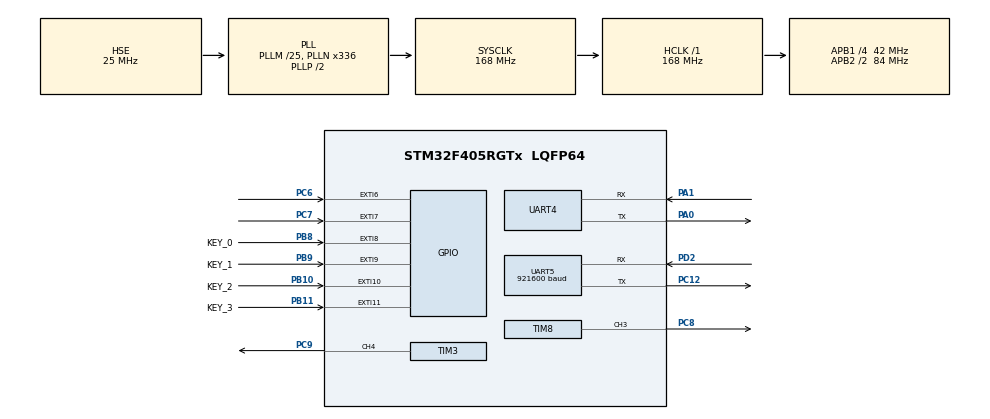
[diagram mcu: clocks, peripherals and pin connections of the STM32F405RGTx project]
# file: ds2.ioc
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Dma.Request0=UART4_RX
Dma.UART4_RX.0.Direction=DMA_PERIPH_TO_MEMORY
Dma.UART4_RX.0.FIFOMode=DMA_FIFOMODE_DISABLE
Dma.UART4_RX.0.Instance=DMA1_Stream2
Dma.UART4_RX.0.MemDataAlignment=DMA_MDATAALIGN_BYTE
Dma.UART4_RX.0.MemInc=DMA_MINC_ENABLE
Dma.UART4_RX.0.Mode=DMA_CIRCULAR
Dma.UART4_RX.0.PeriphDataAlignment=DMA_PDATAALIGN_BYTE
Dma.UART4_RX.0.PeriphInc=DMA_PINC_DISABLE
Dma.UART4_RX.0.Priority=DMA_PRIORITY_MEDIUM
Mcu.Family=STM32F4
Mcu.Name=STM32F405RGTx
Mcu.Package=LQFP64
NVIC.DMA1_Stream2_IRQn=true\:0\:0\:false\:false\:true\:false\:true\:true
NVIC.EXTI15_10_IRQn=true\:3\:0\:true\:false\:true\:true\:true\:true
NVIC.EXTI9_5_IRQn=true\:2\:0\:true\:false\:true\:true\:true\:true
NVIC.PriorityGroup=NVIC_PRIORITYGROUP_4
NVIC.TIM4_IRQn=true\:1\:0\:true\:false\:true\:true\:true\:true
NVIC.UART4_IRQn=true\:0\:0\:true\:false\:true\:true\:true\:true
PA0-WKUP.Mode=Asynchronous
PA0-WKUP.Signal=UART4_TX
PA1.Mode=Asynchronous
PA1.Signal=UART4_RX
PA13.Mode=Serial_Wire
PA13.Signal=SYS_JTMS-SWDIO
PA14.Mode=Serial_Wire
PA14.Signal=SYS_JTCK-SWCLK
PB10.GPIO_Label=KEY_2
PB10.GPIO_ModeDefaultEXTI=GPIO_MODE_IT_FALLING
PB10.GPIO_PuPd=GPIO_PULLUP
PB10.Signal=GPXTI10
PB11.GPIO_Label=KEY_3
PB11.GPIO_ModeDefaultEXTI=GPIO_MODE_IT_FALLING
PB11.GPIO_PuPd=GPIO_PULLUP
PB11.Signal=GPXTI11
PB8.GPIO_Label=KEY_0
PB8.GPIO_ModeDefaultEXTI=GPIO_MODE_IT_FALLING
PB8.GPIO_PuPd=GPIO_PULLUP
PB8.Signal=GPXTI8
PB9.GPIO_Label=KEY_1
PB9.GPIO_ModeDefaultEXTI=GPIO_MODE_IT_FALLING
PB9.GPIO_PuPd=GPIO_PULLUP
PB9.Signal=GPXTI9
PC12.Mode=Asynchronous
PC12.Signal=UART5_TX
PC6.GPIO_ModeDefaultEXTI=GPIO_MODE_IT_FALLING
PC6.GPIO_PuPd=GPIO_PULLUP
PC6.Signal=GPXTI6
PC7.GPIO_ModeDefaultEXTI=GPIO_MODE_IT_FALLING
PC7.GPIO_PuPd=GPIO_PULLUP
PC7.Signal=GPXTI7
PC8.Signal=S_TIM8_CH3
PC9.Signal=S_TIM3_CH4
PD2.Mode=Asynchronous
PD2.Signal=UART5_RX
PH0-OSC_IN.Mode=HSE-External-Oscillator
PH0-OSC_IN.Signal=RCC_OSC_IN
PH1-OSC_OUT.Mode=HSE-External-Oscillator
PH1-OSC_OUT.Signal=RCC_OSC_OUT
ProjectManager.HeapSize=0x200
ProjectManager.StackSize=0x400
ProjectManager.TargetToolchain=MDK-ARM V5.32
RCC.48MHZClocksFreq_Value=84000000
RCC.AHBFreq_Value=168000000
RCC.APB1CLKDivider=RCC_HCLK_DIV4
RCC.APB1Freq_Value=42000000
RCC.APB1TimFreq_Value=84000000
RCC.APB2CLKDivider=RCC_HCLK_DIV2
RCC.APB2Freq_Value=84000000
RCC.APB2TimFreq_Value=168000000
RCC.CortexFreq_Value=168000000
RCC.HCLKFreq_Value=168000000
RCC.HSE_VALUE=25000000
RCC.HSI_VALUE=16000000
RCC.LSE_VALUE=32768
RCC.PLLM=25
RCC.PLLN=336
RCC.PLLSourceVirtual=RCC_PLLSOURCE_HSE
RCC.SYSCLKFreq_VALUE=168000000
RCC.SYSCLKSource=RCC_SYSCLKSOURCE_PLLCLK
RCC.VCOOutputFreq_Value=336000000
SH.S_TIM3_CH4.0=TIM3_CH4,PWM Generation4 CH4
SH.S_TIM8_CH3.0=TIM8_CH3,PWM Generation3 CH3
TIM3.Channel-PWM\ Generation4\ CH4=TIM_CHANNEL_4
TIM3.Period=20000-1
TIM3.Prescaler=84-1
TIM3.Pulse-PWM\ Generation4\ CH4=2500
TIM4.Period=500-1
TIM4.Prescaler=84-1
TIM8.Channel-PWM\ Generation3\ CH3=TIM_CHANNEL_3
TIM8.Period=20000-1
TIM8.Prescaler=168-1
TIM8.Pulse-PWM\ Generation3\ CH3=2500
UART4.VirtualMode=Asynchronous
UART5.BaudRate=921600
UART5.VirtualMode=Asynchronous
VP_TIM3_VS_ClockSourceINT.Mode=Internal
VP_TIM4_VS_ClockSourceINT.Mode=Internal
VP_TIM8_VS_ClockSourceINT.Mode=Internal
board=custom

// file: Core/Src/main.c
/* USER CODE BEGIN Header */
/**
  ******************************************************************************
  * @file           : main.c
  * @brief          : Main program body
  ******************************************************************************
  * @attention
  *
  * Copyright (c) 2023 STMicroelectronics.
  * All rights reserved.
  *
  * This software is licensed under terms that can be found in the LICENSE file
  * in the root directory of this software component.
  * If no LICENSE file comes with this software, it is provided AS-IS.
  *
  ******************************************************************************
  */
/* USER CODE END Header */
#include "main.h"
#include "dma.h"
#include "tim.h"
#include "usart.h"
#include "gpio.h"

/* USER CODE BEGIN Includes */
#include "packet.h"
#include "imu_data_decode.h"
#include "visual communication.h"
/* USER CODE END Includes */

void SystemClock_Config(void);

/* USER CODE BEGIN 0 */
extern uint8_t visual_data[12];
extern uint8_t Txbuf_v[1];
/* USER CODE END 0 */

int main(void)
{

  /* MCU Configuration--------------------------------------------------------*/

  /* Reset of all peripherals, Initializes the Flash interface and the Systick. */
  HAL_Init();

  /* Configure the system clock */
  SystemClock_Config();

  /* Initialize all configured peripherals */
  MX_GPIO_Init();
  MX_DMA_Init();
  MX_TIM3_Init();
  MX_TIM4_Init();
  MX_TIM8_Init();
  MX_UART4_Init();
  MX_UART5_Init();
  /* USER CODE BEGIN 2 */
	//imu_data_decode_init();
	HAL_TIM_Base_Start_IT(&htim4);
	HAL_TIM_PWM_Stop(&htim3, TIM_CHANNEL_4);
	HAL_TIM_PWM_Stop(&htim8, TIM_CHANNEL_3);
//	HAL_TIM_PWM_Start(&htim3, TIM_CHANNEL_4);
//	HAL_TIM_PWM_Start(&htim8, TIM_CHANNEL_3);
	Visual_init(visual_data,12);
	//__HAL_UART_ENABLE_IT(&huart5, UART_IT_RXNE);
	__HAL_UART_ENABLE_IT(&huart4, UART_IT_IDLE);

  /* USER CODE END 2 */

  /* Infinite loop */
  while (1)
  {

  }
}

void SystemClock_Config(void)
{
  RCC_OscInitTypeDef RCC_OscInitStruct = {0};
  RCC_ClkInitTypeDef RCC_ClkInitStruct = {0};

  /** Configure the main internal regulator output voltage
  */
  __HAL_RCC_PWR_CLK_ENABLE();
  __HAL_PWR_VOLTAGESCALING_CONFIG(PWR_REGULATOR_VOLTAGE_SCALE1);

  /** Initializes the RCC Oscillators according to the specified parameters
  * in the RCC_OscInitTypeDef structure.
  */
  RCC_OscInitStruct.OscillatorType = RCC_OSCILLATORTYPE_HSE;
  RCC_OscInitStruct.HSEState = RCC_HSE_ON;
  RCC_OscInitStruct.PLL.PLLState = RCC_PLL_ON;
  RCC_OscInitStruct.PLL.PLLSource = RCC_PLLSOURCE_HSE;
  RCC_OscInitStruct.PLL.PLLM = 25;
  RCC_OscInitStruct.PLL.PLLN = 336;
  RCC_OscInitStruct.PLL.PLLP = RCC_PLLP_DIV2;
  RCC_OscInitStruct.PLL.PLLQ = 4;
  if (HAL_RCC_OscConfig(&RCC_OscInitStruct) != HAL_OK)
  {
    Error_Handler();
  }

  /** Initializes the CPU, AHB and APB buses clocks
  */
  RCC_ClkInitStruct.ClockType = RCC_CLOCKTYPE_HCLK|RCC_CLOCKTYPE_SYSCLK
                              |RCC_CLOCKTYPE_PCLK1|RCC_CLOCKTYPE_PCLK2;
  RCC_ClkInitStruct.SYSCLKSource = RCC_SYSCLKSOURCE_PLLCLK;
  RCC_ClkInitStruct.AHBCLKDivider = RCC_SYSCLK_DIV1;
  RCC_ClkInitStruct.APB1CLKDivider = RCC_HCLK_DIV4;
  RCC_ClkInitStruct.APB2CLKDivider = RCC_HCLK_DIV2;

  if (HAL_RCC_ClockConfig(&RCC_ClkInitStruct, FLASH_LATENCY_5) != HAL_OK)
  {
    Error_Handler();
  }
}

void Error_Handler(void)
{
  __disable_irq();
  while (1)
  {
  }
}
